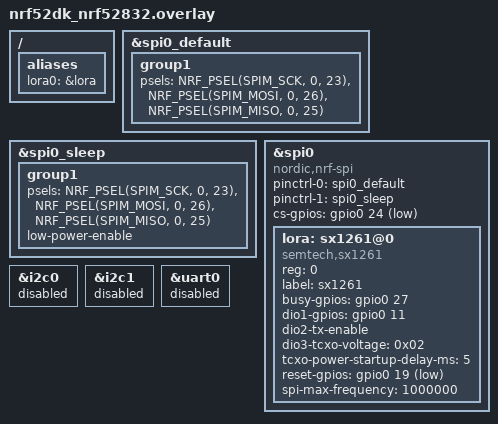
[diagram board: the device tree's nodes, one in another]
// To get started, press Ctrl+Space to bring up the completion menu and view the available nodes.

// You can also use the buttons in the sidebar to perform actions on nodes.
// Actions currently available include:

// * Enabling / disabling the node
// * Adding the bus to a bus
// * Removing the node
// * Connecting ADC channels

// For more help, browse the DeviceTree documentation at https://docs.zephyrproject.org/latest/guides/dts/index.html
// You can also visit the nRF DeviceTree extension documentation at https://nrfconnect.github.io/vscode-nrf-connect/devicetree/nrfdevicetree.html

&spi0_default {
	group1 {
		psels = <NRF_PSEL(SPIM_SCK, 0, 23)>,
			<NRF_PSEL(SPIM_MOSI, 0, 26)>,
			<NRF_PSEL(SPIM_MISO, 0, 25)>;
	};
};

&spi0_sleep {
	group1 {
		psels = <NRF_PSEL(SPIM_SCK, 0, 23)>,
			<NRF_PSEL(SPIM_MOSI, 0, 26)>,
			<NRF_PSEL(SPIM_MISO, 0, 25)>;
		low-power-enable;
	};
};

&spi0 {
	compatible = "nordic,nrf-spi";
	pinctrl-0 = <&spi0_default>;
	pinctrl-1 = <&spi0_sleep>;
	cs-gpios = < &gpio0 24 GPIO_ACTIVE_LOW >;
	//miso-pull-up;
	status = "okay";

	lora: sx1261@0 {
		status = "okay";
		compatible = "semtech,sx1261";
		reg = <0>;
		label = "sx1261";
		busy-gpios = < &gpio0 27 (GPIO_ACTIVE_HIGH )>;
		dio1-gpios = < &gpio0 11 (GPIO_ACTIVE_HIGH) >;
		dio2-tx-enable;
		dio3-tcxo-voltage = < 0x02 >;
		tcxo-power-startup-delay-ms = < 5 >;
		reset-gpios = < &gpio0 19 GPIO_ACTIVE_LOW >;
		spi-max-frequency = <1000000>;
	};
};

/ {
    aliases {
       lora0 = &lora;
  	};
};

&i2c0 {
	status = "disabled";
};

&i2c1 {
	status = "disabled";
};

&uart0 {
	status = "disabled";
};
